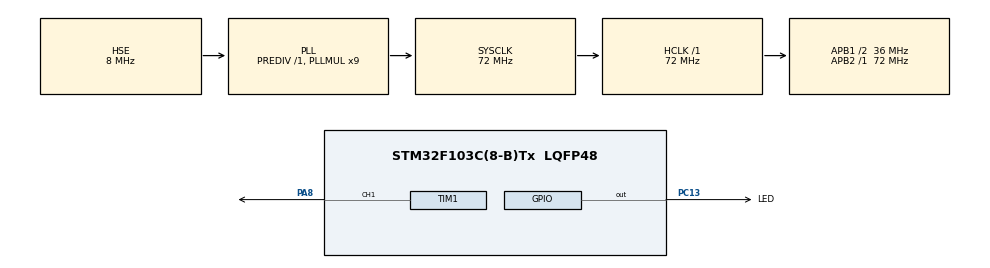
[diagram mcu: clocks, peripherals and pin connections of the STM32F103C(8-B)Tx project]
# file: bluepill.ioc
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Dma.Request0=TIM1_CH1
Dma.TIM1_CH1.0.Direction=DMA_MEMORY_TO_PERIPH
Dma.TIM1_CH1.0.Instance=DMA1_Channel2
Dma.TIM1_CH1.0.MemDataAlignment=DMA_MDATAALIGN_BYTE
Dma.TIM1_CH1.0.MemInc=DMA_MINC_ENABLE
Dma.TIM1_CH1.0.Mode=DMA_NORMAL
Dma.TIM1_CH1.0.PeriphDataAlignment=DMA_PDATAALIGN_WORD
Dma.TIM1_CH1.0.PeriphInc=DMA_PINC_DISABLE
Dma.TIM1_CH1.0.Priority=DMA_PRIORITY_LOW
Mcu.Family=STM32F1
Mcu.Name=STM32F103C(8-B)Tx
Mcu.Package=LQFP48
NVIC.DMA1_Channel2_IRQn=true\:0\:0\:false\:false\:true\:false\:true
NVIC.PriorityGroup=NVIC_PRIORITYGROUP_4
PA13.Mode=Serial_Wire
PA13.Signal=SYS_JTMS-SWDIO
PA14.Mode=Serial_Wire
PA14.Signal=SYS_JTCK-SWCLK
PA8.Signal=S_TIM1_CH1
PC13-TAMPER-RTC.GPIO_Label=LED
PC13-TAMPER-RTC.Signal=GPIO_Output
PD0-OSC_IN.Mode=HSE-External-Oscillator
PD0-OSC_IN.Signal=RCC_OSC_IN
PD1-OSC_OUT.Mode=HSE-External-Oscillator
PD1-OSC_OUT.Signal=RCC_OSC_OUT
ProjectManager.HeapSize=0x200
ProjectManager.StackSize=0x400
ProjectManager.TargetToolchain=STM32CubeIDE
RCC.AHBFreq_Value=72000000
RCC.APB1CLKDivider=RCC_HCLK_DIV2
RCC.APB1Freq_Value=36000000
RCC.APB1TimFreq_Value=72000000
RCC.APB2Freq_Value=72000000
RCC.APB2TimFreq_Value=72000000
RCC.HCLKFreq_Value=72000000
RCC.HSICalibrationValue=8
RCC.PLLMUL=RCC_PLL_MUL9
RCC.PLLSourceVirtual=RCC_PLLSOURCE_HSE
RCC.SYSCLKFreq_VALUE=72000000
RCC.SYSCLKSource=RCC_SYSCLKSOURCE_PLLCLK
RCC.USBFreq_Value=72000000
SH.S_TIM1_CH1.0=TIM1_CH1,PWM Generation1 CH1
TIM1.AutoReloadPreload=TIM_AUTORELOAD_PRELOAD_DISABLE
TIM1.Channel-PWM\ Generation1\ CH1=TIM_CHANNEL_1
TIM1.Period=90-1
VP_TIM1_VS_ClockSourceINT.Mode=Internal
board=custom

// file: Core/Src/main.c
/* USER CODE BEGIN Header */
/**
 ******************************************************************************
 * @file           : main.c
 * @brief          : Main program body
 ******************************************************************************
 * @attention
 *
 * <h2><center>&copy; Copyright (c) 2021 STMicroelectronics.
 * All rights reserved.</center></h2>
 *
 * This software component is licensed by ST under BSD 3-Clause license,
 * the "License"; You may not use this file except in compliance with the
 * License. You may obtain a copy of the License at:
 *                        opensource.org/licenses/BSD-3-Clause
 *
 ******************************************************************************
 */
/* USER CODE END Header */
#include "main.h"

/* USER CODE BEGIN PD */

#define numberofpixels 3
#define bytesperpixel 3
//https://cdn-shop.adafruit.com/datasheets/WS2812.pdf
	//neopixel understands a bit as high when it sees a pwm with 64% duty cycle
#define bitHightimercount 58 //if our pwm period is 90, 64%(90)=57.6 close to 58
	//neopixel understands a bit as low when it sees a pwm with 32% duty cycle
#define bitLowtimercount 29  //if our pwm period is 90, 32%(90)=28.8 close to 29

/* USER CODE END PD */

TIM_HandleTypeDef htim1;
DMA_HandleTypeDef hdma_tim1_ch1;

/* USER CODE BEGIN PV */

//we need 3 neopixel bytes (r g b) to set the colour of every pixel.
//we need 8 PWM cycles to transmit 1 neopixel byte.
//we need 1 uint8_t to be loaded in TIM1->CCR1 for every PWM cycle.
uint8_t rgbw_arr[numberofpixels * bytesperpixel * 8 + 1];//every pixel colour info is 24 bytes long

/* USER CODE END PV */

void SystemClock_Config(void);
static void MX_GPIO_Init(void);
static void MX_DMA_Init(void);
static void MX_TIM1_Init(void);
/* USER CODE BEGIN PFP */

void flushArrayPixel(//zeroes the array
		uint8_t *buffer, //address of our buffer
		uint8_t bytenumber //number of bytes to erase
		) {
	for (uint32_t i = 0; i < bytenumber-1; ++i) {
		buffer[i] = bitLowtimercount;
	}
	buffer[bytenumber] = 0;//needs to be 0 to silent PWM at the end of transaction
}

uint32_t loadArrayOnePixel(uint8_t R, uint8_t G, uint8_t B,
		uint8_t *buffer, //address of our buffer
		uint8_t pixelnumber //pixel index inside buffer
		) {
	if(pixelnumber>numberofpixels){return -1;}//in case we mess up

	for (uint32_t i = 0; i < bytesperpixel * 8; ++i) { //we need to store every bit

		if (i < 8) { //this means first byte R
			if (R & (0x80 >> i)) { //this is a mask for reading every bit inside the byte R
				buffer[i + pixelnumber * bytesperpixel * 8] = bitHightimercount;
			} else {
				buffer[i + pixelnumber * bytesperpixel * 8] = bitLowtimercount;
			}
		}

		if ((i >= 8) & (i < 16)) { //this means second byte G
			if (G & (0x80 >> (i - 8))) {
				buffer[i + pixelnumber * bytesperpixel * 8] = bitHightimercount;
			} else {
				buffer[i + pixelnumber * bytesperpixel * 8] = bitLowtimercount;
			}
		}

		if ((i >= 16) & (i < 24)) { //this means third byte B
			if (B & (0x80 >> (i - 16))) {
				buffer[i + pixelnumber * bytesperpixel * 8] = bitHightimercount;
			} else {
				buffer[i + pixelnumber * bytesperpixel * 8] = bitLowtimercount;
			}
		}

	}
	return 1;
}

/* USER CODE END PFP */

int main(void) {

	/* MCU Configuration--------------------------------------------------------*/

	/* Reset of all peripherals, Initializes the Flash interface and the Systick. */
	HAL_Init();

	/* Configure the system clock */
	SystemClock_Config();

	/* Initialize all configured peripherals */
	MX_GPIO_Init();
	MX_DMA_Init();
	MX_TIM1_Init();
	/* USER CODE BEGIN 2 */
	//flush buffer first
	flushArrayPixel(&rgbw_arr, sizeof(rgbw_arr));

	//for led effect
	uint8_t counter=0;
	uint8_t flag=0;

	/* USER CODE END 2 */

	/* Infinite loop */
	/* USER CODE BEGIN WHILE */
	while (1) {

		//dont know why exactly yet but DMA needs to be stopped before trigger it again
		HAL_TIM_PWM_Stop_DMA(&htim1, TIM_CHANNEL_1);

		/////////////////////////////////////////////////////blue soft pulse of every pixel
		for (uint32_t i = 0; i < numberofpixels; ++i) {
				loadArrayOnePixel(0,0,counter,&rgbw_arr,i);
		}

		HAL_TIM_PWM_Start_DMA(&htim1, TIM_CHANNEL_1, &rgbw_arr,sizeof(rgbw_arr));

		if(counter==0xFF){flag=0;}

		if(counter==0x00){flag=1;}

		if(flag){
			counter++;
		}else{
			counter--;
		}
		/////////////////////////////////////////////////////
		HAL_GPIO_TogglePin(LED_GPIO_Port, LED_Pin);
		HAL_Delay(10);

		/* USER CODE END WHILE */

	}
}

void SystemClock_Config(void) {
	RCC_OscInitTypeDef RCC_OscInitStruct = { 0 };
	RCC_ClkInitTypeDef RCC_ClkInitStruct = { 0 };

	/** Initializes the RCC Oscillators according to the specified parameters
	 * in the RCC_OscInitTypeDef structure.
	 */
	RCC_OscInitStruct.OscillatorType = RCC_OSCILLATORTYPE_HSE;
	RCC_OscInitStruct.HSEState = RCC_HSE_ON;
	RCC_OscInitStruct.HSEPredivValue = RCC_HSE_PREDIV_DIV1;
	RCC_OscInitStruct.HSIState = RCC_HSI_ON;
	RCC_OscInitStruct.PLL.PLLState = RCC_PLL_ON;
	RCC_OscInitStruct.PLL.PLLSource = RCC_PLLSOURCE_HSE;
	RCC_OscInitStruct.PLL.PLLMUL = RCC_PLL_MUL9;
	if (HAL_RCC_OscConfig(&RCC_OscInitStruct) != HAL_OK) {
		Error_Handler();
	}
	/** Initializes the CPU, AHB and APB buses clocks
	 */
	RCC_ClkInitStruct.ClockType = RCC_CLOCKTYPE_HCLK | RCC_CLOCKTYPE_SYSCLK
			| RCC_CLOCKTYPE_PCLK1 | RCC_CLOCKTYPE_PCLK2;
	RCC_ClkInitStruct.SYSCLKSource = RCC_SYSCLKSOURCE_PLLCLK;
	RCC_ClkInitStruct.AHBCLKDivider = RCC_SYSCLK_DIV1;
	RCC_ClkInitStruct.APB1CLKDivider = RCC_HCLK_DIV2;
	RCC_ClkInitStruct.APB2CLKDivider = RCC_HCLK_DIV1;

	if (HAL_RCC_ClockConfig(&RCC_ClkInitStruct, FLASH_LATENCY_2) != HAL_OK) {
		Error_Handler();
	}
}

static void MX_TIM1_Init(void) {

	TIM_ClockConfigTypeDef sClockSourceConfig = { 0 };
	TIM_MasterConfigTypeDef sMasterConfig = { 0 };
	TIM_OC_InitTypeDef sConfigOC = { 0 };
	TIM_BreakDeadTimeConfigTypeDef sBreakDeadTimeConfig = { 0 };

	htim1.Instance = TIM1;
	htim1.Init.Prescaler = 0;
	htim1.Init.CounterMode = TIM_COUNTERMODE_UP;
	htim1.Init.Period = 90 - 1;
	htim1.Init.ClockDivision = TIM_CLOCKDIVISION_DIV1;
	htim1.Init.RepetitionCounter = 0;
	htim1.Init.AutoReloadPreload = TIM_AUTORELOAD_PRELOAD_DISABLE;
	if (HAL_TIM_Base_Init(&htim1) != HAL_OK) {
		Error_Handler();
	}
	sClockSourceConfig.ClockSource = TIM_CLOCKSOURCE_INTERNAL;
	if (HAL_TIM_ConfigClockSource(&htim1, &sClockSourceConfig) != HAL_OK) {
		Error_Handler();
	}
	if (HAL_TIM_PWM_Init(&htim1) != HAL_OK) {
		Error_Handler();
	}
	sMasterConfig.MasterOutputTrigger = TIM_TRGO_RESET;
	sMasterConfig.MasterSlaveMode = TIM_MASTERSLAVEMODE_DISABLE;
	if (HAL_TIMEx_MasterConfigSynchronization(&htim1, &sMasterConfig)
			!= HAL_OK) {
		Error_Handler();
	}
	sConfigOC.OCMode = TIM_OCMODE_PWM1;
	sConfigOC.Pulse = 0;
	sConfigOC.OCPolarity = TIM_OCPOLARITY_HIGH;
	sConfigOC.OCNPolarity = TIM_OCNPOLARITY_HIGH;
	sConfigOC.OCFastMode = TIM_OCFAST_DISABLE;
	sConfigOC.OCIdleState = TIM_OCIDLESTATE_RESET;
	sConfigOC.OCNIdleState = TIM_OCNIDLESTATE_RESET;
	if (HAL_TIM_PWM_ConfigChannel(&htim1, &sConfigOC, TIM_CHANNEL_1)
			!= HAL_OK) {
		Error_Handler();
	}
	sBreakDeadTimeConfig.OffStateRunMode = TIM_OSSR_DISABLE;
	sBreakDeadTimeConfig.OffStateIDLEMode = TIM_OSSI_DISABLE;
	sBreakDeadTimeConfig.LockLevel = TIM_LOCKLEVEL_OFF;
	sBreakDeadTimeConfig.DeadTime = 0;
	sBreakDeadTimeConfig.BreakState = TIM_BREAK_DISABLE;
	sBreakDeadTimeConfig.BreakPolarity = TIM_BREAKPOLARITY_HIGH;
	sBreakDeadTimeConfig.AutomaticOutput = TIM_AUTOMATICOUTPUT_DISABLE;
	if (HAL_TIMEx_ConfigBreakDeadTime(&htim1, &sBreakDeadTimeConfig)
			!= HAL_OK) {
		Error_Handler();
	}
	HAL_TIM_MspPostInit(&htim1);

}

static void MX_DMA_Init(void) {

	/* DMA controller clock enable */
	__HAL_RCC_DMA1_CLK_ENABLE();

	/* DMA interrupt init */
	/* DMA1_Channel2_IRQn interrupt configuration */
	HAL_NVIC_SetPriority(DMA1_Channel2_IRQn, 0, 0);
	HAL_NVIC_EnableIRQ(DMA1_Channel2_IRQn);

}

static void MX_GPIO_Init(void) {
	GPIO_InitTypeDef GPIO_InitStruct = { 0 };

	/* GPIO Ports Clock Enable */
	__HAL_RCC_GPIOC_CLK_ENABLE();
	__HAL_RCC_GPIOD_CLK_ENABLE();
	__HAL_RCC_GPIOA_CLK_ENABLE();

	/*Configure GPIO pin Output Level */
	HAL_GPIO_WritePin(LED_GPIO_Port, LED_Pin, GPIO_PIN_RESET);

	/*Configure GPIO pin : LED_Pin */
	GPIO_InitStruct.Pin = LED_Pin;
	GPIO_InitStruct.Mode = GPIO_MODE_OUTPUT_PP;
	GPIO_InitStruct.Pull = GPIO_NOPULL;
	GPIO_InitStruct.Speed = GPIO_SPEED_FREQ_LOW;
	HAL_GPIO_Init(LED_GPIO_Port, &GPIO_InitStruct);

}

void Error_Handler(void) {
}

/************************ (C) COPYRIGHT STMicroelectronics *****END OF FILE****/
